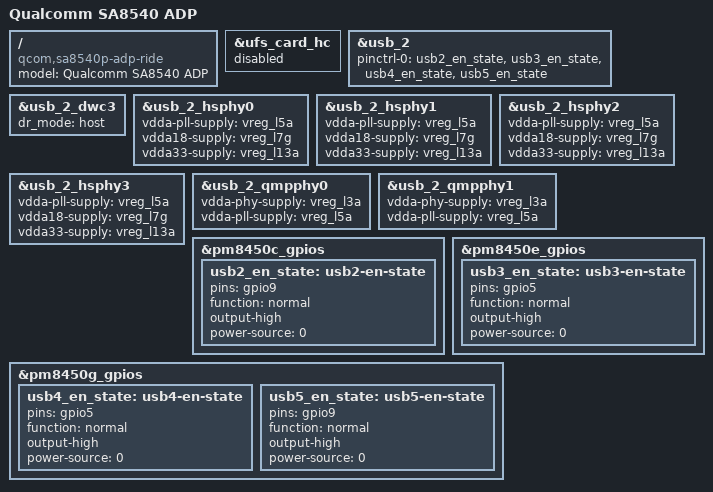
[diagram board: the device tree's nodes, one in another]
// SPDX-License-Identifier: BSD-3-Clause
/*
 * Copyright (c) 2021, The Linux Foundation. All rights reserved.
 * Copyright (c) 2022, Linaro Limited
 * Copyright (c) 2022, Qualcomm Innovation Center, Inc. All rights reserved.
 */

/dts-v1/;

#include "sa8540p-adp.dtsi"

/ {
	model = "Qualcomm SA8540 ADP";
	compatible = "qcom,sa8540p-adp-ride", "qcom,sa8540p";
};

&ufs_card_hc {
	/* Currently broken on this board */
	status = "disabled";
};

&usb_2 {
	status = "okay";

	pinctrl-names = "default";
	pinctrl-0 = <&usb2_en_state>, <&usb3_en_state>, <&usb4_en_state>, <&usb5_en_state>;
};

&usb_2_dwc3 {
	dr_mode = "host";
};

&usb_2_hsphy0 {
	status = "okay";

	vdda-pll-supply = <&vreg_l5a>;
	vdda18-supply = <&vreg_l7g>;
	vdda33-supply = <&vreg_l13a>;
};

&usb_2_hsphy1 {
	status = "okay";

	vdda-pll-supply = <&vreg_l5a>;
	vdda18-supply = <&vreg_l7g>;
	vdda33-supply = <&vreg_l13a>;
};

&usb_2_hsphy2 {
	status = "okay";

	vdda-pll-supply = <&vreg_l5a>;
	vdda18-supply = <&vreg_l7g>;
	vdda33-supply = <&vreg_l13a>;
};

&usb_2_hsphy3 {
	status = "okay";

	vdda-pll-supply = <&vreg_l5a>;
	vdda-pll-supply = <&vreg_l5a>;
	vdda18-supply = <&vreg_l7g>;
	vdda33-supply = <&vreg_l13a>;
};

&usb_2_qmpphy0 {
	status = "okay";

	vdda-phy-supply = <&vreg_l3a>;
	vdda-pll-supply = <&vreg_l5a>;
};

&usb_2_qmpphy1 {
	status = "okay";

	vdda-phy-supply = <&vreg_l3a>;
	vdda-pll-supply = <&vreg_l5a>;
};

/* PINCTRL */
&pm8450c_gpios {
	usb2_en_state: usb2-en-state {
		pins = "gpio9";
		function = "normal";
		output-high;
		power-source = <0>;
	};
};

&pm8450e_gpios {
	usb3_en_state: usb3-en-state {
		pins = "gpio5";
		function = "normal";
		output-high;
		power-source = <0>;
	};
};

&pm8450g_gpios {
	usb4_en_state: usb4-en-state {
		pins = "gpio5";
		function = "normal";
		output-high;
		power-source = <0>;
	};

	usb5_en_state: usb5-en-state {
		pins = "gpio9";
		function = "normal";
		output-high;
		power-source = <0>;
	};
};
